VERSION ""

NS_ :

BS_:

BU_: XXX 1

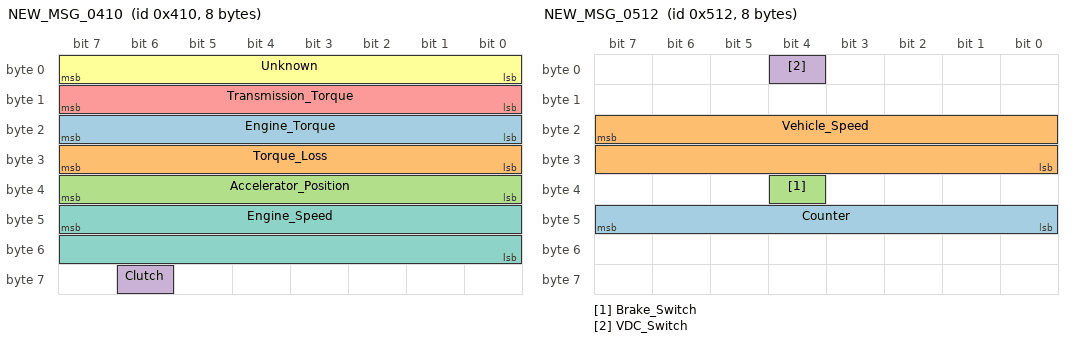
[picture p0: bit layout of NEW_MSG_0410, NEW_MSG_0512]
BO_ 1040 NEW_MSG_0410: 8 XXX
 SG_ Engine_Torque : 16|8@1+ (1,0) [0|255] "" XXX
 SG_ Torque_Loss : 24|8@1+ (1,0) [0|255] "" XXX
 SG_ Accelerator_Position : 32|8@1+ (1,0) [0|255] "" XXX
 SG_ Clutch : 62|1@0+ (1,0) [0|1] "" XXX
 SG_ Transmission_Torque : 8|8@1+ (1,0) [0|255] "" XXX
 SG_ Unknown : 0|8@1+ (1,0) [0|255] "" XXX
 SG_ Engine_Speed : 47|16@0+ (1,0) [0|65535] "" XXX

BO_ 1298 NEW_MSG_0512: 8 XXX
 SG_ Counter : 40|8@1+ (1,0) [0|255] "" XXX
 SG_ Vehicle_Speed : 23|16@0+ (0.05625,0) [0|65535] "km/hr" XXX
 SG_ Brake_Switch : 36|1@0+ (1,0) [0|1] "" XXX
 SG_ VDC_Switch : 4|1@0+ (1,0) [0|1] "" XXX

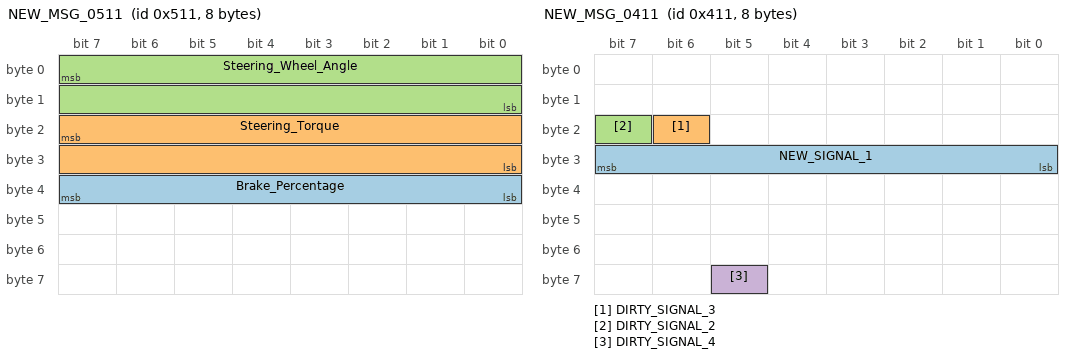
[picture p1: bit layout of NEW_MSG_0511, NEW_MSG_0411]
BO_ 1297 NEW_MSG_0511: 8 XXX
 SG_ Brake_Percentage : 32|8@1+ (1,0) [0|255] "" XXX
 SG_ Steering_Torque : 23|16@0+ (1,0) [0|65535] "" XXX
 SG_ Steering_Wheel_Angle : 7|16@0+ (1,0) [0|65535] "" XXX

BO_ 1281 NEW_MSG_0501: 8 XXX
 SG_ Counter : 40|8@1+ (1,0) [0|255] "" XXX
 SG_ All_On_Byte4 : 24|8@1+ (1,0) [0|255] "" XXX

BO_ 1041 NEW_MSG_0411: 8 XXX
 SG_ NEW_SIGNAL_1 : 24|8@1+ (1,0) [0|255] "" XXX
 SG_ DIRTY_SIGNAL_3 : 22|1@0+ (1,0) [0|1] "" XXX
 SG_ DIRTY_SIGNAL_2 : 23|1@0+ (1,0) [0|1] "" XXX
 SG_ DIRTY_SIGNAL_4 : 61|1@0+ (1,0) [0|1] "" XXX

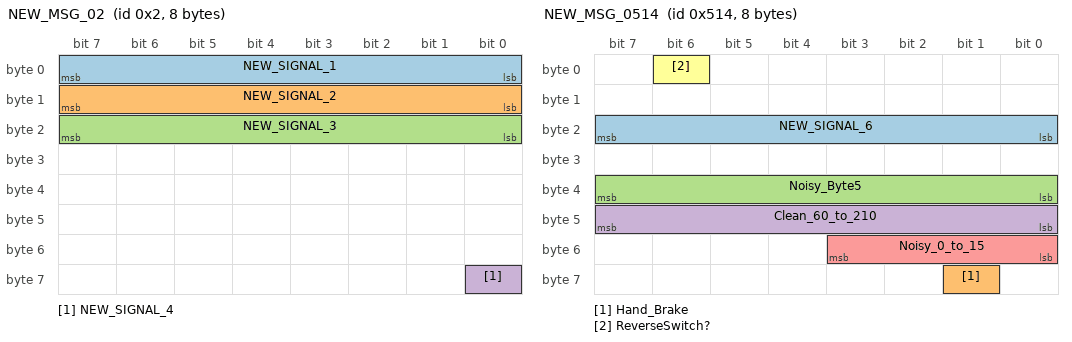
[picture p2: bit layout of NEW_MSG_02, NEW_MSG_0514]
BO_ 2 NEW_MSG_02: 8 XXX
 SG_ NEW_SIGNAL_1 : 0|8@1+ (1,0) [0|255] "" XXX
 SG_ NEW_SIGNAL_2 : 8|8@1+ (1,0) [0|255] "" XXX
 SG_ NEW_SIGNAL_3 : 16|8@1+ (1,0) [0|255] "" XXX
 SG_ NEW_SIGNAL_4 : 56|1@0+ (1,0) [0|1] "" XXX

BO_ 1042 NEW_MSG_0412: 8 XXX
 SG_ NEW_SIGNAL_1 : 7|16@0+ (1,0) [0|65535] "" XXX
 SG_ NEW_SIGNAL_2 : 23|16@0+ (1,0) [0|65535] "" XXX
 SG_ NEW_SIGNAL_4 : 40|8@1+ (1,0) [0|255] "" XXX
 SG_ NEW_SIGNAL_3 : 31|8@0+ (1,0) [0|65535] "" XXX

BO_ 1537 NEW_MSG_0601: 8 XXX
 SG_ NEW_SIGNAL_1 : 31|16@0+ (1,0) [0|65535] "" XXX

BO_ 1300 NEW_MSG_0514: 8 XXX
 SG_ NEW_SIGNAL_6 : 16|8@1+ (1,0) [0|255] "" XXX
 SG_ Hand_Brake : 57|1@0+ (1,0) [0|1] "" XXX
 SG_ Noisy_Byte5 : 32|8@1+ (1,0) [0|255] "" XXX
 SG_ Clean_60_to_210 : 40|8@1+ (1,0) [0|255] "" XXX
 SG_ Noisy_0_to_15 : 48|4@1+ (1,0) [0|15] "" XXX
 SG_ ReverseSwitch? : 6|1@0+ (1,0) [0|1] "" XXX

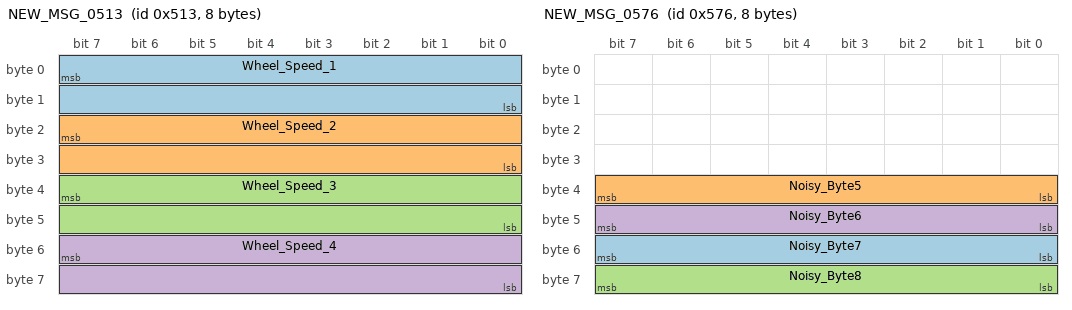
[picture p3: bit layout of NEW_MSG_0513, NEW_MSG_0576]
BO_ 1299 NEW_MSG_0513: 8 XXX
 SG_ Wheel_Speed_1 : 7|16@0+ (0.005625,0) [0|65535] "" XXX
 SG_ Wheel_Speed_2 : 23|16@0+ (0.005625,0) [0|65535] "" XXX
 SG_ Wheel_Speed_3 : 39|16@0+ (0.005625,0) [0|65535] "" XXX
 SG_ Wheel_Speed_4 : 55|16@0+ (0.005625,0) [0|65535] "" XXX

BO_ 1398 NEW_MSG_0576: 8 XXX
 SG_ Noisy_Byte7 : 48|8@1+ (1,0) [0|255] "" XXX
 SG_ Noisy_Byte5 : 32|8@1+ (1,0) [0|255] "" XXX
 SG_ Noisy_Byte8 : 56|8@1+ (1,0) [0|255] "" XXX
 SG_ Noisy_Byte6 : 40|8@1+ (1,0) [0|255] "" XXX

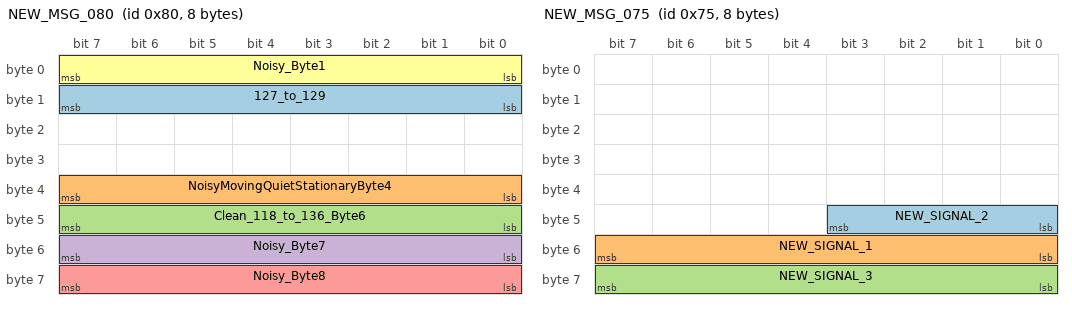
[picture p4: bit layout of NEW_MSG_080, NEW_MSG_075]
BO_ 128 NEW_MSG_080: 8 XXX
 SG_ 127_to_129 : 8|8@1+ (1,0) [0|255] "" XXX
 SG_ NoisyMovingQuietStationaryByte4 : 32|8@1+ (1,0) [0|255] "" XXX
 SG_ Clean_118_to_136_Byte6 : 40|8@1+ (1,0) [0|255] "" XXX
 SG_ Noisy_Byte7 : 48|8@1+ (1,0) [0|255] "" XXX
 SG_ Noisy_Byte8 : 56|8@1+ (1,0) [0|255] "" XXX
 SG_ Noisy_Byte1 : 0|8@1+ (1,0) [0|255] "" XXX

BO_ 112 NEW_MSG_070: 8 XXX
 SG_ Steering_Related : 7|9@1+ (1,0) [0|255] "" XXX
 SG_ Noisy_Byte1 : 0|8@1+ (1,0) [0|255] "" XXX
 SG_ Noisy_Byte5 : 32|8@1+ (1,0) [0|255] "" XXX
 SG_ Clean_Byte6 : 40|8@1+ (1,0) [0|255] "" XXX

BO_ 1568 NEW_MSG_0620: 8 XXX
 SG_ NEW_SIGNAL_1 : 16|8@1+ (1,0) [0|255] "" XXX
 SG_ NEW_SIGNAL_2 : 0|8@1+ (1,0) [0|255] "" XXX

BO_ 117 NEW_MSG_075: 8 XXX
 SG_ NEW_SIGNAL_2 : 40|4@1+ (1,0) [0|15] "" XXX
 SG_ NEW_SIGNAL_1 : 48|8@1+ (1,0) [0|255] "" XXX
 SG_ NEW_SIGNAL_3 : 56|8@1+ (1,0) [0|255] "" XXX

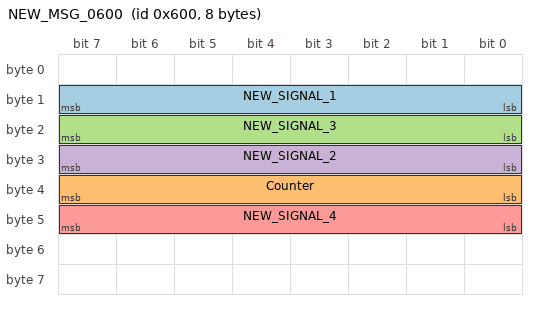
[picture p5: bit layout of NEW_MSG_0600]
BO_ 1536 NEW_MSG_0600: 8 XXX
 SG_ NEW_SIGNAL_1 : 8|8@1+ (1,0) [0|255] "" XXX
 SG_ Counter : 32|8@1+ (1,0) [0|255] "" XXX
 SG_ NEW_SIGNAL_3 : 16|8@1+ (1,0) [0|255] "" XXX
 SG_ B : NaN|NaN@0+ (4,8) [NaN|8] "," 1
 SG_ NEW_SIGNAL_2 : 24|8@1+ (1,0) [0|255] "" XXX
 SG_ NEW_SIGNAL_4 : 40|8@1+ (1,0) [0|255] "" XXX
